# SHM Register Definitions: IP-XACT component
VLNV meklort:<PROJECT>:SHM Register Definitions:1.0

## Address spaces and blocks
SHM.SHM: base 0xC0014000, range , width 
SHM_CHANNEL0.SHM_CHANNEL0: base 0xC0014900, range , width 
SHM_CHANNEL1.SHM_CHANNEL1: base 0xC0014a00, range , width 
SHM_CHANNEL2.SHM_CHANNEL2: base 0xC0014b00, range , width 
SHM_CHANNEL3.SHM_CHANNEL3: base 0xC0014c00, range , width 

## Registers
Registers are 32-bit, access not given, no defined reset value unless marked. A register's access mark holds for its fields unless they carry their own. Offsets are from the block's base; lines under a group give offsets from that group; [hi:lo] are bit positions; {n}, {i} and the like mark numbered series; 'fields as' and 'values as' point back to an identical list; <NAME> marks a mode.

## SHM.SHM — Device APE SHM Registers
Base 0xC0014000
0x00 SEG_SIG rw — APE_APE_MAGIC ('APE!') when all is well.
  [31:0] Sig
    0x10AD10AD=LOADER
0x04 APE_SEG_LENGTH — Set to 0x34.
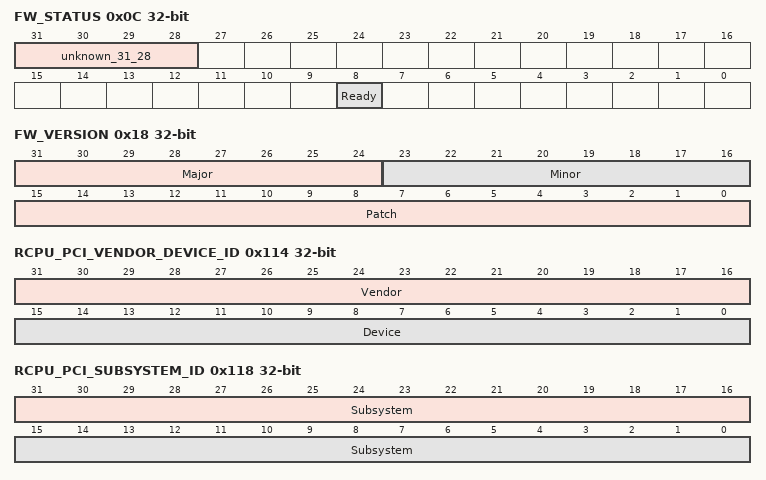
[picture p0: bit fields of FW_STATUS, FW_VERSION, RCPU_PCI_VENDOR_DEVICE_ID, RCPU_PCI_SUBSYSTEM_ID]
0x0C FW_STATUS rw
  [31:28] unknown_31_28 — If this is all-ones, it appears to mean the APE FW is halted.
  [8] Ready
0x10 FW_FEATURES rw
  [1] NCSI
0x14 4014
0x18 FW_VERSION rw
  [31:24] Major, [23:16] Minor, [15:0] Patch
0x1C SEG_MESSAGE_BUFFER_OFFSET — Specifies the offset of a scratchpad area, relative to the start of the APE SHM area (i.e., relative to APE_REG(0x4000)).
0x20 SEG_MESSAGE_BUFFER_LENGTH — Specifies the size of the scratchpad area in bytes.
0x24 4024 — Unknown. Bootcode related.
0x28 4028 — Unknown. Bootcode related.
{0x30+4i} Driver_Buffer[{i}] (i=0..1) — Communication channel between the host driver and the APE.
0x38 Loader_Command rw — Command sent when using the the APE loader. Zero once handled.
  [31:0] Command
    0=NOP; 1=READ_MEM; 2=WRITE_MEM; 3=CALL
0x3C Loader_Arg0 — Argument 0 for the APE loader.
0x40 Loader_Arg1 — Argument 1 for the APE loader.
0x100 RCPU_SEG_SIG rw — Set to APE_RCPU_MAGIC ('RCPU') by RX CPU.
  [31:0] Sig
    0x52435055=RCPU_MAGIC
0x104 RCPU_SEG_LENGTH — Set to 0x34.
0x108 RCPU_INIT_COUNT — Incremented by RX CPU every boot.
0x10C RCPU_FW_VERSION — Set to the bootcode version. e.g. 0x0127 -> v1.39.
0x110 RCPU_CFG_FEATURE — Set to
0x114 RCPU_PCI_VENDOR_DEVICE_ID rw — Set to PCI Vendor/Device ID by S2.
  [31:16] Vendor ID, [15:0] Device ID
0x118 RCPU_PCI_SUBSYSTEM_ID rw — Set to PCI Subsystem Vendor/Subsystem ID by S2.
  [31:16] Subsystem ID, [15:0] Subsystem Vendor ID
0x11C RCPU_APE_RESET_COUNT — Unknown. Incremented by frobnicating routine.
0x120 RCPU_LAST_APE_STATUS — Unknown. Written by frobnicating routine.
0x124 RCPU_LAST_APE_FW_STATUS
0x128 RCPU_CFG_HW — Set from
0x12C RCPU_CFG_HW_2 — Set from
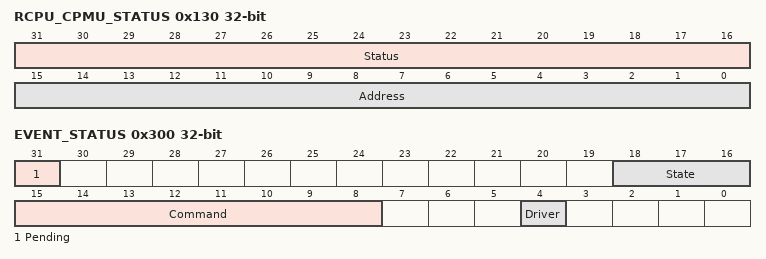
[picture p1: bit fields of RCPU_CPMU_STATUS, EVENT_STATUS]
0x130 RCPU_CPMU_STATUS rw — Set from
  [31:16] Status
  [15:0] Address
    0x362C=ADDRESS
0x200 HOST_SEG_SIG — Set to APE_HOST_MAGIC ('HOST') to indicate the section is valid.
0x204 HOST_SEG_LEN — Set to 0x20.
0x208 HOST_INIT_COUNT — Incremented by host on every initialization.
0x20C HOST_DRIVER_ID — Linux sets this to 0xF0MM_mm00, where M is the major version of Linux and m is the minor version.
0x210 HOST_BEHAVIOR rw
  [0] No PHYLock
0x214 HEARTBEAT_INTERVAL — In milliseconds. Set to 0 to disable heartbeating.
0x218 HEARTBEAT_COUNT
0x21C HOST_DRIVER_STATE rw
  [31:0] State
    1=Start; 2=Unload; 3=WOL
0x224 WOL_SPEED
0x300 EVENT_STATUS rw
  [31] Pending
  [18:16] State
    1=Start; 2=Unload; 3=WOL; 4=Suspend
  [15:8] Command
    5=State Change; 22=Scratchpad Read; 23=Scratchpad Write
  [4] Driver Event
0x308 PROT_MAGIC — This is set to APE_PROT_MAGIC ('PROT') on all functions. If it is 'PROT', the following fields (MAC0_HIGH/LOW) are valid
0x314 PROT_MAC0_HIGH — High 16 bits of MAC address 0. Only valid if
0x318 PROT_MAC0_LOW — Low 16 bits of MAC address 0.
0x324 RCPU Write Pointer — Index into the printf buffer for last valid byte.
0x328 RCPU Host Read Pointer — Index into the printf buffer for last read byte.
0x32C RCPU Read Pointer — Index into the printf buffer for last read byte.
{0x330+4i} RCPU Printf Buffer[{i}] (i=0..371) — Printf buffer from the APE to the Rcpu for NVRAM printout or the host

## SHM_CHANNEL0.SHM_CHANNEL0 — Device APE SHM Channel Registers
Base 0xC0014900
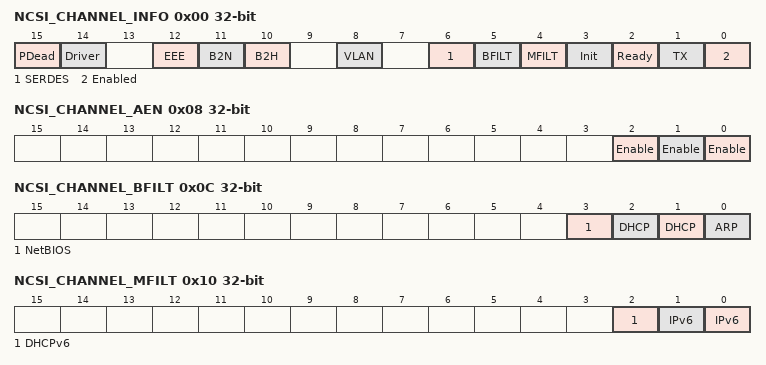
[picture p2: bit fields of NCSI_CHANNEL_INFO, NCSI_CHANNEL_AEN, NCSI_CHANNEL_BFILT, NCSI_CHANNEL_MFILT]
0x00 NCSI_CHANNEL_INFO rw
  [15] PDead
  [14] Driver
  [12] EEE
  [11] B2N
  [10] B2H
  [8] VLAN
  [6] SERDES
  [5] BFILT
  [4] MFILT
  [3] Init
  [2] Ready
  [1] TX Passthrough — TX passthrough has been enabled by BMC NCSI command.
  [0] Enabled — This can be modified via NCSI SELECT PACKAGE and NCSI DESELECT PACKAGE.
0x04 NCSI_CHANNEL_MCID — AEN Management Controller ID, set by BMC when sending AEN ENABLE command and used when sending AENs.
0x08 NCSI_CHANNEL_AEN rw — Set via NCSI ENABLE AEN.
  [2] Enable Host NC Driver Status Change AEN, [1] Enable Configuration Required AEN, [0] Enable Link Status Change AEN
0x0C NCSI_CHANNEL_BFILT rw
  [3] NetBIOS Packet, [2] DHCP Server Packet, [1] DHCP Client Packet, [0] ARP Packet
0x10 NCSI_CHANNEL_MFILT rw
  [2] DHCPv6 Relay and Server Multicast, [1] IPv6 Router Advertisement, [0] IPv6 Neighbour Advertisement
0x14 NCSI_CHANNEL_SETTING_1 rw — This is the "Link Settings" value from NCSI Set Link.
  [12] OEM link settings field valid, [11] Asymmetric pause capability enable, [10] Pause capability enable, [9] Full duplex enable, [8] Half duplex enable, [4] Link Speed 10G enable, [3] Link Speed 1000M enable, [2] Link Speed 100M enable, [2] Link Speed 100M enable, [1] Link Speed 10M enable, [0] Autonegotiation enabled
0x18 NCSI_CHANNEL_SETTING_2 — This is the "OEM Settings" value from NCSI Set Link.
0x1C NCSI_CHANNEL_VLAN — Receives VLAN mode from NCSI specification "Enable VLAN" command.
0x24 NCSI_CHANNEL_ALT_HOST_MAC_HIGH — Lower 16 bits of this word contains upper 16 bits of the MAC.
0x28 NCSI_CHANNEL_ALT_HOST_MAC_MID — Lower 16 bits of this word contains mid 16 bits of the MAC.
0x2C NCSI_CHANNEL_ALT_HOST_MAC_LOW — Lower 16 bits of this word contains low 16 bits of the MAC.
{0x34+0x10*i} NCSI_CHANNEL_MAC{i}_HIGH (i=0..3) — Lower 16 bits of this word contains upper 16 bits of the MAC.
{0x38+0x10*i} NCSI_CHANNEL_MAC{i}_MID (i=0..3) — Lower 16 bits of this word contains mid 16 bits of the MAC.
{0x3C+0x10*i} NCSI_CHANNEL_MAC{i}_LOW (i=0..3) — Lower 16 bits of this word contains low 16 bits of the MAC.
0x70 NCSI_CHANNEL_MAC0_VLAN_VALID — Nonzero indicates VLAN field is valid
0x74 NCSI_CHANNEL_MAC0_VLAN
0x78 NCSI_CHANNEL_MAC1_VLAN_VALID — Nonzero indicates VLAN field is valid
0x7C NCSI_CHANNEL_MAC1_VLAN
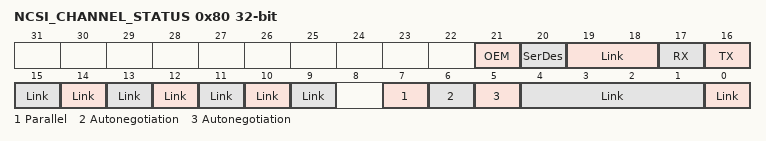
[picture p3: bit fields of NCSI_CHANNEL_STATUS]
0x80 NCSI_CHANNEL_STATUS rw
  [21] OEM Link Status Valid — If set, OEM Link Status was populated and is valid.
  [20] SerDes Link — SerDes status.
  [19:18] Link Partner Advertised Flow Control — Flow control supported by partner.
    0=Not Capable; 1=Symmetric Pause; 2=Asymmetric Pause; 3=Symmetric and Asymmetric Pause
  [17] RX Flow Control Flag — Pause Flow Control enabled for RX on the external network interface.
  [16] TX Flow Control Flag — Pause Flow Control enabled for TX on the external network interface.
  [15] Link Speed 10M-T Half Duplex Capable — Link partner 10BASE-T half-duplex capable
  [14] Link Speed 10M-T Full Duplex Capable — Link partner 10BASE-T full-duplex capable
  [13] Link Speed 100M-TX Half Duplex Capable — Link partner 100BASE-TX half-duplex capable
  [12] Link Speed 100M-TX Full Duplex Capable — Link partner 100BASE-TX full-duplex capable
  [11] Link Speed 100M-T4 Capable — Link partner is 100BASE-T4 capable
  [10] Link Speed 1000M Half Duplex Capable — Link partner is 1000BASE-T half-duplex capable
  [9] Link Speed 1000M Full Duplex Capable — Link partner is 1000BASE-T full-duplex capable
  [7] Parallel Detection — Link partner did not support auto-negotiation and parallel detection was used to get link.
  [6] Autonegotiation Complete — Set if autonegotiation is complete.
  [5] Autonegotiation Enabled — Auto-negotiation is enabled. This field always returns 0 if auto-negotiation is not supported.
  [4:1] Link Status
    0=No Link; 1=10BASE-T half-duplex; 2=10BASE-T full-duplex; 3=100BASE-TX half-duplex; 4=100BASE-T4; 5=100BASE-TX full-duplex; 6=1000BASE-T half-duplex; 7=1000BASE-T full-duplex; 8=10G-BASE-T
  [0] Link up
0x84 NCSI_CHANNEL_RESET_COUNT
0x88 NCSI_CHANNEL_PXE
0x8C NCSI_CHANNEL_DROPFIL
0x90 NCSI_CHANNEL_SLINK
0xA0 NCSI_CHANNEL_DBG
0xB0 NCSI_CHANNEL_NETWORK_RX — Number of packets received from the external network interface
0xB4 NCSI_CHANNEL_NETWORK_TX — Number of packets transmited from the BCM5719 to external network interface
0xB8 NCSI_CHANNEL_NCSI_RX — Number of packets received from the BMC via NCSI
0xBC NCSI_CHANNEL_NCSI_TX — Number of packets transmitted from the BCM5719 to the BMC via NCSI
0xC0 NCSI_CHANNEL_NCSI_DROPPED — Number of packets dropped on the NCSI interface.
0xC4 NCSI_CHANNEL_NETWORK_DROPPED — Number of packets dropped on the external network interface.
0xC8 NCSI_CHANNEL_AEN — Number of AEN packets sent via NCSI
